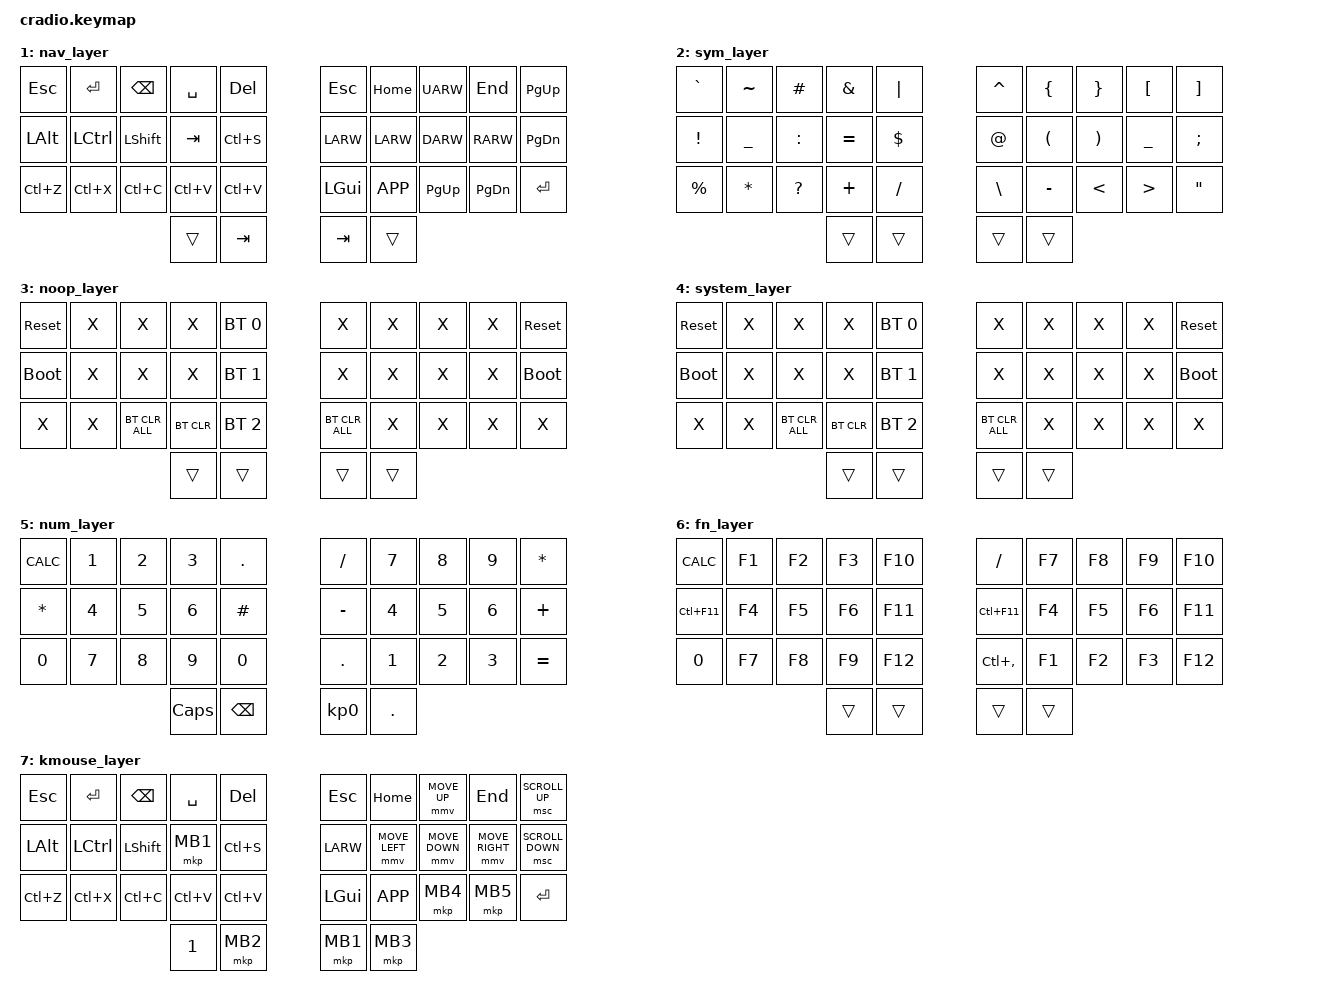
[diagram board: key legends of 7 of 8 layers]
// Copyright (c) 2022 The ZMK Contributors
// SPDX-License-Identifier: MIT

#include <behaviors.dtsi>
#include <dt-bindings/zmk/keys.h>
#include <dt-bindings/zmk/bt.h>
#include <dt-bindings/zmk/mouse.h>

// Home row mods macro
#define HRML(k1,k2,k3,k4) &homey_lt 5 k1  &homey_lt 2 k2   &homey_left LSHFT k3  &shift_left LSHFT k4
#define HRMR(k1,k2,k3,k4) &shift_right RSHFT k1  &homey_right RSHFT k2  &homey_rt 2 k3  &homey_rt 5 k4

&mmv {
  acceleration-exponent = <1>;      // 1
  time-to-max-speed-ms = <1500>;    // 40
  delay-ms = <0>;                   // 0
};

&msc {
  acceleration-exponent = <1>;      // 0
  time-to-max-speed-ms = <5000>;    // 40
  delay-ms = <0>;                   // 10
};

#define U_MOUSE_MOVE_MAX 1250       // 600
#define U_MOUSE_SCROLL_MAX 100      // 10

#undef MOVE_UP
#undef MOVE_DOWN
#undef MOVE_LEFT
#undef MOVE_RIGHT
#define MOVE_UP MOVE_Y(-U_MOUSE_MOVE_MAX)
#define MOVE_DOWN MOVE_Y(U_MOUSE_MOVE_MAX)
#define MOVE_LEFT MOVE_X(-U_MOUSE_MOVE_MAX)
#define MOVE_RIGHT MOVE_X(U_MOUSE_MOVE_MAX)

#undef SCROLL_UP
#undef SCROLL_DOWN
#undef SCROLL_LEFT
#undef SCROLL_RIGHT
#define SCROLL_UP SCRL_Y(U_MOUSE_SCROLL_MAX)
#define SCROLL_DOWN SCRL_Y(-U_MOUSE_SCROLL_MAX)
#define SCROLL_LEFT SCRL_X(-U_MOUSE_SCROLL_MAX)
#define SCROLL_RIGHT SCRL_X(U_MOUSE_SCROLL_MAX)


/ {
    behaviors {
        ht: hold_tap {
            compatible = "zmk,behavior-hold-tap";
            #binding-cells = <2>;
            flavor = "tap-preferred";
            tapping-term-ms = <220>;
            quick-tap-ms = <150>;
            require-prior-idle-ms = <100>;
            bindings = <&kp>, <&kp>;
        };

		//////////////////////////////////////////////////////////////////////////
		//
		// Miryoku layers and home row mods (ported from my QMK endgame)
		// - https://sunaku.github.io/home-row-mods.html#porting-to-zmk
		// - https://github.com/urob/zmk-config#timeless-homerow-mods
		//
		//////////////////////////////////////////////////////////////////////////

		//
		// HOMEY_HOLDING_TYPE defines the flavor of ZMK hold-tap behavior to use
		// for the pinky, ring, and middle fingers (which are assigned to Super,
		// Alt, and Ctrl respectively in the Miryoku system) on home row keys.
		//
		#ifndef HOMEY_HOLDING_TYPE
		#define HOMEY_HOLDING_TYPE "balanced"
		#endif

		//
		// HOMEY_HOLDING_TIME defines how long you need to hold (milliseconds)
		// home row mod keys in order to send their modifiers to the computer
		// (i.e. "register" them) for mod-click mouse usage (e.g. Ctrl-Click).
		//
		#ifndef HOMEY_HOLDING_TIME
		#define HOMEY_HOLDING_TIME 2000 // TAPPING_TERM + ALLOW_CROSSOVER_AFTER
		#endif

		//
		// HOMEY_STREAK_DECAY defines how long you need to wait (milliseconds)
		// after typing before you can use home row mods again.  It prevents
		// unintended activation of home row mods when you're actively typing.
		//
		#ifndef HOMEY_STREAK_DECAY
		#define HOMEY_STREAK_DECAY 170 // global-quick-tap-ms
		#endif

		//
		// HOMEY_REPEAT_DECAY defines how much time you have left (milliseconds)
		// after tapping a key to hold it again in order to make it auto-repeat.
		//
		#ifndef HOMEY_REPEAT_DECAY
		#define HOMEY_REPEAT_DECAY 300 // "tap then hold" for key auto-repeat
		#endif

		//
		// SHIFT_HOLDING_TYPE defines the flavor of ZMK hold-tap behavior to use
		// for index fingers (which Miryoku assigns to Shift) on home row keys.
		//
		// NOTE: The "tap-preferred" flavor of ZMK hold-tap for index finger keys
		// allows faster activation of the Shift modifier (without having to wait
		// for the modified key to be released as the "balanced" flavor requires).
		// Typing streaks and the `hold-trigger-on-release` setting are disabled
		// for the index fingers so as not to hinder their speed and dexterity.
		//
		#ifndef SHIFT_HOLDING_TYPE
		#define SHIFT_HOLDING_TYPE "balanced"
		#endif

		//
		// SHIFT_HOLDING_TIME defines how long you need to hold (milliseconds)
		// index finger keys in order to send their modifiers to the computer
		// (i.e. "register" them) for mod-click mouse usage (e.g. Shift-Click).
		//
		// CAUTION: You'll need to perform inward rolls from pinky->ring->middle
		// fingers toward the index fingers when activating multiple modifiers
		// because `hold-trigger-on-release` is disabled for the index fingers.
		// Otherwise, you may be surprised that the index fingers' modifier is
		// sent immediately without the rest of your multi-mod chord when you
		// perform outward rolls from your index fingers toward your pinkies.
		//
		#ifndef SHIFT_HOLDING_TIME
		#define SHIFT_HOLDING_TIME 170
		#endif

		//
		// SHIFT_STREAK_DECAY defines how long you need to wait (milliseconds)
		// after typing before you can use home row mods again.  It prevents
		// unintended activation of home row mods when you're actively typing.
		//
		#ifndef SHIFT_STREAK_DECAY
		#define SHIFT_STREAK_DECAY 70 // global-quick-tap-ms
		#endif

		//
		// SHIFT_REPEAT_DECAY defines how much time you have left (milliseconds)
		// after tapping a key to hold it again in order to make it auto-repeat.
		//
		#ifndef SHIFT_REPEAT_DECAY
		#define SHIFT_REPEAT_DECAY 300 // "tap then hold" for key auto-repeat
		#endif

		//
		// THUMB_HOLDING_TYPE defines the flavor of ZMK hold-tap behavior to use
		// for the thumbs (which are assigned to 6 layers in the Miryoku system).
		//
		// NOTE: The "balanced" flavor of ZMK hold-tap provides instant modifier
		// activation for the symbol layer (if the tapped symbol key is released
		// while the thumb layer key is still held down) for quicker programming.
		//
		#ifndef THUMB_HOLDING_TYPE
		#define THUMB_HOLDING_TYPE "balanced"
		#endif

		//
		// THUMB_HOLDING_TIME defines how long you need to hold (milliseconds)
		// a thumb key to activate a layer.  Shorter holds are treated as taps.
		//
		#ifndef THUMB_HOLDING_TIME
		#define THUMB_HOLDING_TIME 5000
		#endif

		//
		// THUMB_REPEAT_DECAY defines how much time you have left (milliseconds)
		// after tapping a key to hold it again in order to make it auto-repeat.
		//
		#ifndef THUMB_REPEAT_DECAY
		#define THUMB_REPEAT_DECAY 300 // "tap then hold" for key auto-repeat
		#endif

		//
		// SPACE_HOLDING_TIME defines how long you need to hold (milliseconds)
		// the space thumb key to activate.  Shorter holds are treated as taps.
		//
		#ifndef SPACE_HOLDING_TIME
		#define SPACE_HOLDING_TIME 170
		#endif

		//
		// SPACE_REPEAT_DECAY defines how much time you have left (milliseconds)
		// after tapping a key to hold it again in order to make it auto-repeat.
		//
		#ifndef SPACE_REPEAT_DECAY
		#define SPACE_REPEAT_DECAY 200 // "tap then hold" for key auto-repeat
		#endif

		//
		// Ferris sweep key positions index for positional hold-tap
		//
		// |------------------------|------------------------|
		// | LEFT_HAND_KEYS         |        RIGHT_HAND_KEYS |
		// |                        |                        |
		// |  0  1  2  3  4         |          5  6  7  8  9 |
		// | 10 11 12 13 14         |         15 16 17 18 19 |
		// | 20 21 22 23 24         |      25 26 27 28 29 30 |
		// |	          31 32     |  33 34                 |
		// |------------------------|------------------------|
		//
		#define LEFT_HAND_KEYS  \
			  0  1  2  3  4     \
			 10 11 12 13 14     \
			 20 21 22 23 24

		#define RIGHT_HAND_KEYS     \
										5  6  7  8  9 \
									   15 16 17 18 19 \
									   25 26 27 28 29 30
		#define THUMB_KEYS          \
							31 32       33 34  

		//
		// Home row mod-tap keys for all except index fingers
		//
		homey_left: miryoku_home_row_mods_left_hand {
			compatible = "zmk,behavior-hold-tap";
			label = "HOME_ROW_MODS_LEFT_HAND";
			flavor = HOMEY_HOLDING_TYPE;
			hold-trigger-key-positions = <RIGHT_HAND_KEYS THUMB_KEYS>;
			hold-trigger-on-release; // wait for other home row mods
			tapping-term-ms = <HOMEY_HOLDING_TIME>;
			quick-tap-ms = <HOMEY_REPEAT_DECAY>;
			require-prior-idle-ms = <HOMEY_STREAK_DECAY>;
			#binding-cells = <2>;
			bindings = <&kp>, <&kp>;
		};
		homey_right: miryoku_home_row_mods_right_hand {
			compatible = "zmk,behavior-hold-tap";
			label = "HOME_ROW_MODS_RIGHT_HAND";
			flavor = HOMEY_HOLDING_TYPE;
			hold-trigger-key-positions = <LEFT_HAND_KEYS THUMB_KEYS>;
			hold-trigger-on-release; // wait for other home row mods
			tapping-term-ms = <HOMEY_HOLDING_TIME>;
			quick-tap-ms = <HOMEY_REPEAT_DECAY>;
			require-prior-idle-ms = <HOMEY_STREAK_DECAY>;
			#binding-cells = <2>;
			bindings = <&kp>, <&kp>;
		};

		//
		// Special home row mod-tap keys for the index fingers
		
		shift_left: miryoku_home_row_mods_left_shift_shift {
			compatible = "zmk,behavior-hold-tap";
			label = "HOME_ROW_MODS_LEFT_SHIFT";
			flavor = SHIFT_HOLDING_TYPE;
			hold-trigger-key-positions = <RIGHT_HAND_KEYS THUMB_KEYS>;
			hold-trigger-on-release; // don't wait for other mods
			tapping-term-ms = <SHIFT_HOLDING_TIME>;
			//quick-tap-ms = <SHIFT_REPEAT_DECAY>;
			//require-prior-idle-ms = <SHIFT_STREAK_DECAY>;
			#binding-cells = <2>;
			bindings = <&kp>, <&kp>;
		};
		
		shift_right: miryoku_home_row_mods_right_shift_shift {
			compatible = "zmk,behavior-hold-tap";
			label = "HOME_ROW_MODS_RIGHT_SHIFT";
			flavor = SHIFT_HOLDING_TYPE;
			hold-trigger-key-positions = <LEFT_HAND_KEYS THUMB_KEYS>;
			hold-trigger-on-release; // don't wait for other mods
			tapping-term-ms = <SHIFT_HOLDING_TIME>;
			//quick-tap-ms = <SHIFT_REPEAT_DECAY>;
			//require-prior-idle-ms = <SHIFT_STREAK_DECAY>;
			#binding-cells = <2>;
			bindings = <&kp>, <&kp>;
		}; 
		
		homey_lt: miryoku_home_row_mods_left_layer_tap {
			compatible = "zmk,behavior-hold-tap";
			label = "HOME_ROW_MODS_LEFT_SHIFT_SHIFT";
			flavor = SHIFT_HOLDING_TYPE;
			hold-trigger-key-positions = <RIGHT_HAND_KEYS THUMB_KEYS>;
			hold-trigger-on-release; // don't wait for other mods
			tapping-term-ms = <SHIFT_HOLDING_TIME>;
			//quick-tap-ms = <SHIFT_REPEAT_DECAY>;
			//require-prior-idle-ms = <SHIFT_STREAK_DECAY>;
			#binding-cells = <2>;
			bindings = <&mo>, <&kp>;
		};
	    homey_rt: miryoku_home_row_mods_right_layer_tap {
			compatible = "zmk,behavior-hold-tap";
			label = "HOME_ROW_MODS_RIGHT_SHIFT_SHIFT";
			flavor = SHIFT_HOLDING_TYPE;
			hold-trigger-key-positions = <LEFT_HAND_KEYS THUMB_KEYS>;
			hold-trigger-on-release; // don't wait for other mods
			tapping-term-ms = <SHIFT_HOLDING_TIME>;
			//quick-tap-ms = <SHIFT_REPEAT_DECAY>;
			//require-prior-idle-ms = <SHIFT_STREAK_DECAY>;
			#binding-cells = <2>;
			bindings = <&mo>, <&kp>;
		};

		//
		// Thumb cluster hold-tap keys for Miryoku layers
		//
		thumb: miryoku_thumb_layer {
			compatible = "zmk,behavior-hold-tap";
			label = "MIRYOKU_THUMB_LAYER";
			flavor = THUMB_HOLDING_TYPE;
			tapping-term-ms = <THUMB_HOLDING_TIME>;
			quick-tap-ms = <THUMB_REPEAT_DECAY>; // enable repeat
			//global-quick-tap; // no typing streak
			//retro-tap; // don't allow slow (hold-like) taps
			#binding-cells = <2>;
			bindings = <&mo>, <&kp>;
		};
		backspace: miryoku_backspace_layer {
			compatible = "zmk,behavior-hold-tap";
			label = "MIRYOKU_BACKSPACE_LAYER";
			flavor = "hold-preferred";
			tapping-term-ms = <THUMB_HOLDING_TIME>;
			quick-tap-ms = <THUMB_REPEAT_DECAY>; // enable repeat
			//global-quick-tap; // no typing streak
			//retro-tap; // don't allow slow (hold-like) taps
			#binding-cells = <2>;
			bindings = <&mo>, <&kp>;
		};
		space: miryoku_thumb_layer_spacebar {
			compatible = "zmk,behavior-hold-tap";
			label = "MIRYOKU_THUMB_LAYER_SPACEBAR";
			flavor = THUMB_HOLDING_TYPE;
			tapping-term-ms = <SPACE_HOLDING_TIME>;
			quick-tap-ms = <SPACE_REPEAT_DECAY>; // enable repeat
			//global-quick-tap; // no typing streak
			retro-tap; // allow slow (hold-like) taps
			#binding-cells = <2>;
			bindings = <&mo>, <&kp>;
		};

		//////////////////////////////////////////////////////////////////////////
		//
		// Custom shifted pairs
		//
		//////////////////////////////////////////////////////////////////////////

		//
		// Shift + CapsWord = CapsLock
		//
		cappy: capsword_and_capslock {
			compatible = "zmk,behavior-mod-morph";
			label = "CAPSWORD_AND_CAPSLOCK";
			#binding-cells = <0>;
			bindings = <&caps_word>, <&kp CAPSLOCK>;
			mods = <(MOD_LSFT|MOD_RSFT)>;
		};

		//////////////////////////////////////////////////////////////////////////
		//
		// ZMK global overrides
		//
		//////////////////////////////////////////////////////////////////////////

		//
		// CapsWord - ported from Pascal Getreuer's extension for QMK
		// - https://zmk.dev/docs/behaviors/caps-word
		// - https://getreuer.info/posts/keyboards/caps-word/index.html
		//
		behavior_caps_word {
			continue-list = <
				UNDERSCORE MINUS
				BACKSPACE DELETE
				N1 N2 N3 N4 N5 N6 N7 N8 N9 N0
			>;
		};
	};


    conditional_layers {
        compatible = "zmk,conditional-layers";
        tri_layer {
            if-layers = <1 2>;
            then-layer = <3>;
        };
    };

	//
	// |------------------------|------------------------|
	// | LEFT_HAND_KEYS         |        RIGHT_HAND_KEYS |
	// |                        |                        |
	// |  0  1  2  3  4         |          5  6  7  8  9 |
	// | 10 11 12 13 14         |         15 16 17 18 19 |
	// | 20 21 22 23 24         |         25 26 27 28 29 |
	// |	          30 31     |  32 33                 |
	// |------------------------|------------------------|
	//

    combos {
        compatible = "zmk,combos";
        combo_esc {
            timeout-ms = <50>;
            key-positions = <0 1>;
            bindings = <&kp ESC>;
        };
        combo_find {
            timeout-ms = <50>;
            key-positions = <1 2>;
            bindings = <&kp LC(F)>;
        };
        combo_findfiles {
            timeout-ms = <50>;
            key-positions = <1 2 3>;
            bindings = <&kp LC(LS(F))>;
        };
		combo_lctl {
            timeout-ms = <50>;
            key-positions = <20 21>;
            bindings = <&kp LCTRL>;
        };
        combo_lalt {
            timeout-ms = <50>;
            key-positions = <21 22>;
            bindings = <&kp LALT>;
        };
        combo_lcalt {
            timeout-ms = <50>;
            key-positions = <20 21 22>;
            bindings = <&kp LC(LALT)>;
        };
		combo_rctl {
            timeout-ms = <50>;
            key-positions = <28 29>;
            bindings = <&kp RCTRL>;
        };
        combo_ralt {
            timeout-ms = <50>;
            key-positions = <27 28>;
            bindings = <&kp RALT>;
        }; 
        combo_rcalt {
            timeout-ms = <50>;
            key-positions = <27 28 29>;
            bindings = <&kp RC(RALT)>;
        };
		combo_lgui {
            timeout-ms = <50>;
            key-positions = <30 31>;
            bindings = <&kp LGUI>;
        };
        combo_rgui {
            timeout-ms = <50>;
            key-positions = <32 33>;
            bindings = <&kp RGUI>;
        };
        combo_app {
            timeout-ms = <50>;
            key-positions = <30 31 32 33>;
            bindings = <&kp K_APP>;
        };
	};

    keymap {
        compatible = "zmk,keymap";
        default_layer {
            bindings = <
        //╭──────────┬──────────┬──────────┬──────────┬──────────╮   ╭──────────┬──────────┬──────────┬──────────┬──────────╮
        //│  Q       │  W       │  F       │  P       │  V       │   │  J       │  L       │  U       │  Y       │  P       │
  &homey_left LGUI Q  &homey_lt 7 W  &homey_lt 6 F  &kp P  &kp V       &kp J     &kp L  &homey_rt 6 U   &kp Y     &kp AT 
        //├──────────┼──────────┼──────────┼──────────┼──────────┤   ├──────────┼──────────┼──────────┼──────────┼──────────┤
        //│  A       │  R       │  S       │  T       │  G       │   │  M       │  N       │  E       │  I       │ O        │
            HRML(A,        R,         S,         T)     &kp G          &kp M  HRMR(N,       E,         I,        O)
        //├──────────┼──────────┼──────────┼──────────┼──────────┤   ├──────────┼──────────┼──────────┼──────────┼──────────┤
        //│  Z       │  X       │  C       │  D       │  B       │   │   K      │  H       │ , <      │ . >      │ / ?      │
        &kp Z  &homey_lt 4 X	&kp C      &kp D      &kp B          &kp K    &kp H      &kp COMMA  &homey_rt 4 DOT  &kp SQT
        //╰──────────┴──────────┴──────────┼──────────┼──────────┤   ├──────────┼──────────┼──────────┴──────────┴──────────╯
                        &homey_left LSHFT ENTER  &backspace 1 BSPC  &thumb  1 SPACE  &homey_right RSHFT ENTER
        //                                 ╰──────────┴──────────╯   ╰──────────┴──────────╯
            >;
        };
		
        nav_layer {
            bindings = <	
        //╭──────────┬──────────┬──────────┬──────────┬──────────╮   ╭──────────┬──────────┬──────────┬──────────┬──────────╮
        //│ ESC      │  1       │  2       │  3       │          │   │ HOME     │ PAGE DN  │ PAGE UP  │ END      │  :       │
            &kp ESC    &kp ENTER  &kp BSPC   &kp SPACE  &kp DEL        &kp ESC    &kp HOME   &kp UARW   &kp END    &kp PG_UP
        //├──────────┼──────────┼──────────┼──────────┼──────────┤   ├──────────┼──────────┼──────────┼──────────┼──────────┤
        //│ LALT     │ LCTRL    │ LSHFT    │  TAB     │          │   │ LEFT     │ DOWN     │ UP       │ RIGHT    │  ;       │
            &kp LALT   &kp LCTRL  &kp LSHFT  &kp TAB    &kp LC(S)      &kp LARW   &kp LARW   &kp DARW   &kp RARW   &kp PG_DN
        //├──────────┼──────────┼──────────┼──────────┼──────────┤   ├──────────┼──────────┼──────────┼──────────┼──────────┤
        //│ CAPS     │  7       │  8       │  9       │  0       │   │          │          │          │          │          │
            &kp LC(Z)  &kp LC(X)  &kp LC(C)  &kp LC(V)  &kp LC(V)      &kp LGUI   &kp K_APP  &kp PG_UP   &kp PG_DN &kp ENTER
        //╰──────────┴──────────┴──────────┼──────────┼──────────┤   ├──────────┼──────────┼──────────┴──────────┴──────────╯
                                             &trans    &kp TAB        &kp TAB    &trans    
        //                                 ╰──────────┴──────────╯   ╰──────────┴──────────╯
            >;
        };
		
        sym_layer {
            bindings = <
        //╭──────────┬──────────┬──────────┬──────────┬──────────╮   ╭──────────┬──────────┬──────────┬──────────┬──────────╮
        //│          │  [       │  {       │  }       │          │   │  ^       │  (       │  )       │  ]       │  ~       │
            &kp GRAVE  &kp TILDE  &kp HASH   &kp AMPS   &kp PIPE       &kp CARET  &kp LBRC   &kp RBRC   &kp LBKT   &kp RBKT
        //├──────────┼──────────┼──────────┼──────────┼──────────┤   ├──────────┼──────────┼──────────┼──────────┼──────────┤
        //│  !       │  @       │  #       │  $       │  %       │   │  *       │  -       │  =       │  \       │  `       │
           &kp EXCL   &kp UNDER   &kp COLON  &kp EQUAL  &kp DLLR       &kp AT     &kp LPAR   &kp RPAR   &kp UNDER  &kp SEMI
        //├──────────┼──────────┼──────────┼──────────┼──────────┤   ├──────────┼──────────┼──────────┼──────────┼──────────┤
        //│          │          │          │          │          │   │  &       │  _       │  +       │  │       │          │
            &kp PRCNT  &kp STAR   &kp QMARK  &kp PLUS  &kp SLASH       &kp BSLH  &kp MINUS  &kp LT    &kp GT      &kp DQT
        //╰──────────┴──────────┴──────────┼──────────┼──────────┤   ├──────────┼──────────┼──────────┴──────────┴──────────╯
                                             &trans     &trans         &trans     &trans
        //                                 ╰──────────┴──────────╯   ╰──────────┴──────────╯
            >;
        };

		noop_layer {
            bindings = <
        //╭──────────┬──────────┬──────────┬──────────┬──────────╮   ╭──────────┬──────────┬──────────┬──────────┬──────────╮
        //│ RESET    │          │          │          │PROFILE 0 │   │          │          │          │          │  RESET   │
           &sys_reset  &kp X     &kp X     &kp X    &bt BT_SEL 0      &kp X     &kp X     &kp X     &kp X    &sys_reset
        //├──────────┼──────────┼──────────┼──────────┼──────────┤   ├──────────┼──────────┼──────────┼──────────┼──────────┤
        //│BOOTLOADER│          │          │          │PROFILE 1 │   │          │          │          │          │BOOTLOADER│
          &bootloader  &kp X     &kp X     &kp X    &bt BT_SEL 1       &kp X     &kp X     &kp X     &kp X    &bootloader
        //├──────────┼──────────┼──────────┼──────────┼──────────┤   ├──────────┼──────────┼──────────┼──────────┼──────────┤
        //│          │          │          │ CLEAR BT │PROFILE 2 │   │          │          │          │          │          │
            &kp X     &kp X     &bt BT_CLR_ALL    &bt BT_CLR &bt    BT_SEL 2    &bt BT_CLR_ALL    &kp X     &kp X     &kp X     &kp X
        //╰──────────┴──────────┴──────────┼──────────┼──────────┤   ├──────────┼──────────┼──────────┴──────────┴──────────╯
                                             &trans     &trans         &trans     &trans
        //                                 ╰──────────┴──────────╯   ╰──────────┴──────────╯
            >;
        };

        system_layer {
            bindings = <
        //╭──────────┬──────────┬──────────┬──────────┬──────────╮   ╭──────────┬──────────┬──────────┬──────────┬──────────╮
        //│ RESET    │          │          │          │PROFILE 0 │   │          │          │          │          │  RESET   │
           &sys_reset  &kp X     &kp X     &kp X    &bt BT_SEL 0      &kp X     &kp X     &kp X     &kp X    &sys_reset
        //├──────────┼──────────┼──────────┼──────────┼──────────┤   ├──────────┼──────────┼──────────┼──────────┼──────────┤
        //│BOOTLOADER│          │          │          │PROFILE 1 │   │          │          │          │          │BOOTLOADER│
          &bootloader  &kp X     &kp X     &kp X    &bt BT_SEL 1       &kp X     &kp X     &kp X     &kp X    &bootloader
        //├──────────┼──────────┼──────────┼──────────┼──────────┤   ├──────────┼──────────┼──────────┼──────────┼──────────┤
        //│          │          │          │ CLEAR BT │PROFILE 2 │   │          │          │          │          │          │
            &kp X     &kp X     &bt BT_CLR_ALL    &bt BT_CLR &bt    BT_SEL 2    &bt BT_CLR_ALL    &kp X     &kp X     &kp X     &kp X
        //╰──────────┴──────────┴──────────┼──────────┼──────────┤   ├──────────┼──────────┼──────────┴──────────┴──────────╯
                                             &trans     &trans         &trans     &trans
        //                                 ╰──────────┴──────────╯   ╰──────────┴──────────╯
            >;
        };
		
		num_layer {
            bindings = <
        //╭──────────┬──────────┬──────────┬──────────┬──────────╮   ╭──────────┬──────────┬──────────┬──────────┬──────────╮
        //│ INSERT   │  1       │  2       │  3       │          │   │ HOME     │ PAGE DN  │ PAGE UP  │ END      │  :       │
            &kp K_CALC &kp N1     &kp N2     &kp N3     &kp DOT        &kp SLASH  &kp N7     &kp N8    &kp N9     &kp STAR
        //├──────────┼──────────┼──────────┼──────────┼──────────┤   ├──────────┼──────────┼──────────┼──────────┼──────────┤
        //│ DELETE   │  4       │  5       │  6       │          │   │ LEFT     │ DOWN     │ UP       │ RIGHT    │  ;       │
            &kp STAR   &kp N4     &kp N5     &kp N6     &kp HASH       &kp MINUS  &kp N4     &kp N5     &kp N6     &kp PLUS
        //├──────────┼──────────┼──────────┼──────────┼──────────┤   ├──────────┼──────────┼──────────┼──────────┼──────────┤
        //│ CAPS     │  7       │  8       │  9       │  0       │   │          │          │          │          │          │
            &kp N0     &kp N7     &kp N8     &kp N9     &kp N0         &kp DOT    &kp N1  &kp N2  &kp N3 &kp EQUAL
        //╰──────────┴──────────┴──────────┼──────────┼──────────┤   ├──────────┼──────────┼──────────┴──────────┴──────────╯
                                      &kp CAPSLOCK     &kp BSPC       &kp KP_N0  &kp DOT
        //                                 ╰──────────┴──────────╯   ╰──────────┴──────────╯
            >;
        };

		fn_layer {
            bindings = <
        //╭──────────┬──────────┬──────────┬──────────┬──────────╮   ╭──────────┬──────────┬──────────┬──────────┬──────────╮
        //│ INSERT   │  1       │  2       │  3       │          │   │ HOME     │ PAGE DN  │ PAGE UP  │ END      │  :       │
            &kp K_CALC &kp F1     &kp F2     &kp F3     &kp F10        &kp SLASH  &kp F7     &kp F8     &kp F9     &kp F10
        //├──────────┼──────────┼──────────┼──────────┼──────────┤   ├──────────┼──────────┼──────────┼──────────┼──────────┤
        //│ DELETE   │  4       │  5       │  6       │          │   │ LEFT     │ DOWN     │ UP       │ RIGHT    │  ;       │
            &kp LC(F11) &kp F4    &kp F5     &kp F6     &kp F11        &kp LC(F11)  &kp F4   &kp F5     &kp F6     &kp F11
        //├──────────┼──────────┼──────────┼──────────┼──────────┤   ├──────────┼──────────┼──────────┼──────────┼──────────┤
        //│ CAPS     │  7       │  8       │  9       │  0       │   │          │          │          │          │          │
            &kp N0     &kp F7     &kp F8     &kp F9     &kp F12        &kp LC(COMMA)  &kp F1  &kp F2    &kp F3     &kp F12
        //╰──────────┴──────────┴──────────┼──────────┼──────────┤   ├──────────┼──────────┼──────────┴──────────┴──────────╯
                                             &trans     &trans         &trans     &trans
        //                                 ╰──────────┴──────────╯   ╰──────────┴──────────╯
            >;
        };

		kmouse_layer {
            bindings = <
        //╭──────────┬──────────┬──────────┬──────────┬──────────╮   ╭──────────┬──────────┬──────────┬──────────┬──────────╮
        //│ ESC      │  1       │  2       │  3       │          │   │ HOME     │ PAGE DN  │ PAGE UP  │ END      │  :       │
            &kp ESC    &kp ENTER  &kp BSPC   &kp SPACE  &kp DEL        &kp ESC    &kp HOME   &mmv MOVE_UP &kp END     &msc SCROLL_UP
        //├──────────┼──────────┼──────────┼──────────┼──────────┤   ├──────────┼──────────┼──────────┼──────────┼──────────┤
        //│ LALT     │ LCTRL    │ LSHFT    │  TAB     │          │   │ LEFT     │ DOWN     │ UP       │ RIGHT    │  ;       │
            &kp LALT   &kp LCTRL  &kp LSHFT  &mkp MB1  &kp LC(S)      &kp LARW   &mmv MOVE_LEFT  &mmv MOVE_DOWN  &mmv MOVE_RIGHT  &msc SCROLL_DOWN
        //├──────────┼──────────┼──────────┼──────────┼──────────┤   ├──────────┼──────────┼──────────┼──────────┼──────────┤
        //│ CAPS     │  7       │  8       │  9       │  0       │   │          │          │          │          │          │
            &kp LC(Z)  &kp LC(X)  &kp LC(C)  &kp LC(V)  &kp LC(V)      &kp LGUI   &kp K_APP  &mkp MB4   &mkp MB5   &kp ENTER
        //╰──────────┴──────────┴──────────┼──────────┼──────────┤   ├──────────┼──────────┼──────────┴──────────┴──────────╯
                                             &kp N1     &mkp MB2      &mkp MB1  &mkp MB3
        //                                 ╰──────────┴──────────╯   ╰──────────┴──────────╯
            >;
        };
    };
};
